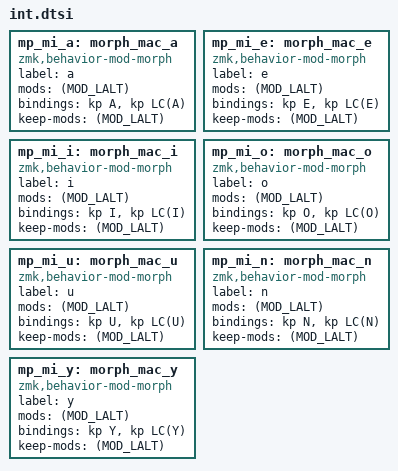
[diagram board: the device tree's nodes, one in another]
mp_mi_a: morph_mac_a {
    compatible = "zmk,behavior-mod-morph";
    label = "a";
    #binding-cells = <0>;
    mods = <(MOD_LALT)>;
    bindings = <&kp A>, <&kp LC(A)>;
    keep-mods = <(MOD_LALT)>;
};

mp_mi_e: morph_mac_e {
    compatible = "zmk,behavior-mod-morph";
    label = "e";
    #binding-cells = <0>;
    mods = <(MOD_LALT)>;
    bindings = <&kp E>, <&kp LC(E)>;
    keep-mods = <(MOD_LALT)>;
};

mp_mi_i: morph_mac_i {
    compatible = "zmk,behavior-mod-morph";
    label = "i";
    #binding-cells = <0>;
    mods = <(MOD_LALT)>;
    bindings = <&kp I>, <&kp LC(I)>;
    keep-mods = <(MOD_LALT)>;
};

mp_mi_o: morph_mac_o {
    compatible = "zmk,behavior-mod-morph";
    label = "o";
    #binding-cells = <0>;
    mods = <(MOD_LALT)>;
    bindings = <&kp O>, <&kp LC(O)>;
    keep-mods = <(MOD_LALT)>;
};

mp_mi_u: morph_mac_u {
    compatible = "zmk,behavior-mod-morph";
    label = "u";
    #binding-cells = <0>;
    mods = <(MOD_LALT)>;
    bindings = <&kp U>, <&kp LC(U)>;
    keep-mods = <(MOD_LALT)>;
};

mp_mi_n: morph_mac_n {
    compatible = "zmk,behavior-mod-morph";
    label = "n";
    #binding-cells = <0>;
    mods = <(MOD_LALT)>;
    bindings = <&kp N>, <&kp LC(N)>;
    keep-mods = <(MOD_LALT)>;
};

mp_mi_y: morph_mac_y {
    compatible = "zmk,behavior-mod-morph";
    label = "y";
    #binding-cells = <0>;
    mods = <(MOD_LALT)>;
    bindings = <&kp Y>, <&kp LC(Y)>;
    keep-mods = <(MOD_LALT)>;
};
